# STM32H7B0 register map
File version: 2.3
CPU: CM7 r0p1, little endian, MPU, FPU, 4 interrupt priority bits
Registers are 32-bit, read-write, reset 0x0 unless marked. A register's access mark holds for its fields unless they carry their own. Offsets are from the block's base; [hi:lo] are bit positions; {n}, {i} and the like mark numbered series; 'fields as' and 'values as' point back to an identical list.

## TIM6 — Basic timers
Base 0x40001000
Same registers: TIM7 0x40001400
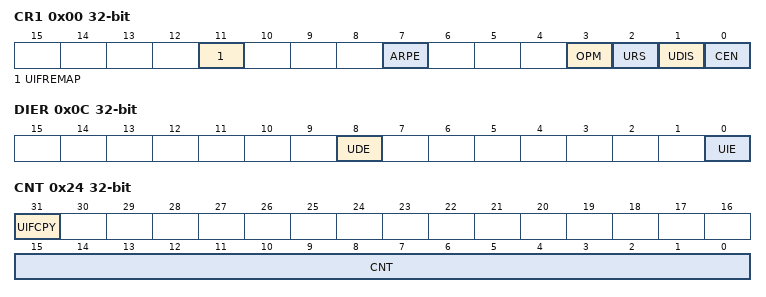
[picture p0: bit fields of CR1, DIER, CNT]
0x00 CR1 — control register 1
  [11] UIFREMAP — UIF status bit remapping
  [7] ARPE — Auto-reload preload enable
  [3] OPM — One-pulse mode
  [2] URS — Update request source
  [1] UDIS — Update disable
  [0] CEN — Counter enable
0x04 CR2 — control register 2
  [6:4] MMS — Master mode selection
0x0C DIER — DMA/Interrupt enable register
  [8] UDE — Update DMA request enable
  [0] UIE — Update interrupt enable
0x10 SR — status register
  [0] UIF — Update interrupt flag
0x14 EGR wo — event generation register
  [0] UG — Update generation
0x24 CNT — counter
  [31] UIFCPY — UIF Copy
  [15:0] CNT — Low counter value
0x28 PSC — prescaler
  [15:0] PSC — Prescaler value
0x2C ARR — auto-reload register
  [15:0] ARR — Low Auto-reload value

## OctoSPII_O_Manager
Base 0x5200B400
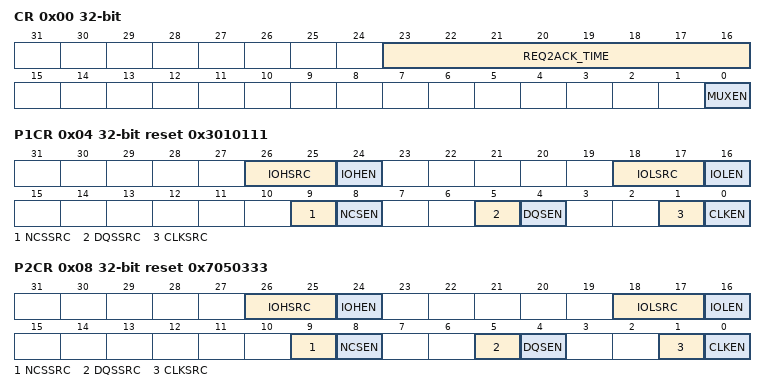
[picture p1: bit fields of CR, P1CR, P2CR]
0x00 CR — OctoSPI IO Manager Control Register
  [23:16] REQ2ACK_TIME — REQ to ACK Time
  [0] MUXEN — Multiplexed mode Enable
0x04 P1CR reset 0x3010111 — OctoSPI IO Manager Port 1 configuration register
  [26:25] IOHSRC
  [24] IOHEN
  [18:17] IOLSRC
  [16] IOLEN
  [9] NCSSRC
  [8] NCSEN
  [5] DQSSRC
  [4] DQSEN
  [1] CLKSRC — CLK/CLKn Source for Port n
  [0] CLKEN — CLK/CLKn Enable for Port n
0x08 P2CR reset 0x7050333 — OctoSPI IO Manager Port 2 configuration register
  [26:25] IOHSRC, [24] IOHEN, [18:17] IOLSRC, [16] IOLEN, [9] NCSSRC, [8] NCSEN, [5] DQSSRC, [4] DQSEN, [1] CLKSRC, [0] CLKEN

## OTFDEC1 — On-The-Fly Decryption engine
Base 0x5200B800
Same registers: OTFDEC2 0x5200BC00
0x00 CR — OTFDEC control register
  [0] ENC — Encryption mode bit
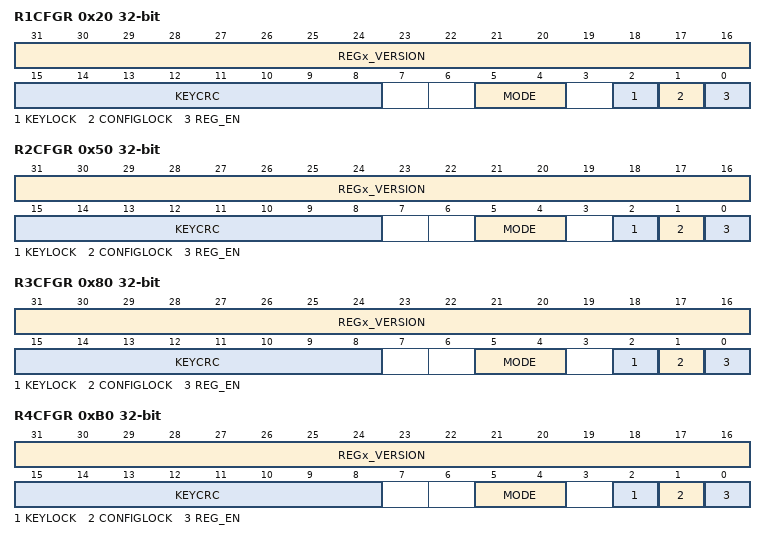
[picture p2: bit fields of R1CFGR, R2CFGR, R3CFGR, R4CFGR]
0x20 R1CFGR access per field — OTFDEC region x configuration register
  [31:16] REGx_VERSION rw — region firmware version
  [15:8] KEYCRC ro — region key 8-bit CRC
  [5:4] MODE rw — operating mode
  [2] KEYLOCK rw — region key lock
  [1] CONFIGLOCK rw — region config lock
  [0] REG_EN rw — region on-the-fly decryption enable
0x24 R1STARTADDR — OTFDEC region x start address register
  [31:0] REGx_START_ADDR — Region AXI start address
0x28 R1ENDADDR reset 0xFFF — OTFDEC region x end address register
  [31:0] REGx_END_ADDR — Region AXI end address
0x2C R1NONCER0 — OTFDEC region x nonce register 0
  [31:0] REGx_NONCE
0x30 R1NONCER1 — OTFDEC region x nonce register 1
  [31:0] REGx_NONCE — Region nonce
{0x4+0x30*i} R{i}KEYR0 wo (i=1..4) — OTFDEC region x key register 0
  [31:0] REGx_KEY
{0x8+0x30*i} R{i}KEYR1 wo (i=1..4) — OTFDEC region x key register 1
  [31:0] REGx_KEY
0x3C R1KEYR2 wo — OTFDEC region x key register 2
  [31:0] REGx_KEY
{0x10+0x30*i} R{i}KEYR3 wo (i=1..4) — OTFDEC region x key register 3
  [31:0] REGx_KEY
0x50 R2CFGR access per field — OTFDEC region x configuration register
  fields as R1CFGR
0x54 R2STARTADDR — OTFDEC region x start address register
  [31:0] REGx_START_ADDR — Region AXI start address
0x58 R2ENDADDR reset 0xFFF — OTFDEC region x end address register
  [31:0] REGx_END_ADDR — Region AXI end address
0x5C R2NONCER0 — OTFDEC region x nonce register 0
  [31:0] REGx_NONCE
0x60 R2NONCER1 — OTFDEC region x nonce register 1
  [31:0] REGx_NONCE — Region nonce, bits [63:32]REGx_NONCE[63:32]
0x6C R2KEYR2 wo — OTFDEC region x key register 2
  [31:0] REGx_KEY_
0x80 R3CFGR access per field — OTFDEC region x configuration register
  fields as R1CFGR
0x84 R3STARTADDR — OTFDEC region x start address register
  [31:0] REGx_START_ADDR — Region AXI start address
0x88 R3ENDADDR reset 0xFFF — OTFDEC region x end address register
  [31:0] REGx_END_ADDR — Region AXI end address
0x8C R4ENDADDR reset 0xFFF — OTFDEC region x end address register
  [31:0] REGx_END_ADDR — Region AXI end address
0x8C R3NONCER0 (alternate view of R4ENDADDR) — OTFDEC region x nonce register 0
  [31:0] REGx_NONCE
0x90 R3NONCER1 — OTFDEC region x nonce register 1
  [31:0] REGx_NONCE
0x9C R3KEYR2 wo — OTFDEC region x key register 2
  [31:0] REGx_KEY
0xB0 R4CFGR access per field — OTFDEC region x configuration register
  fields as R1CFGR
0xB4 R4STARTADDR — OTFDEC region x start address register
  [31:0] REGx_START_ADDR — Region AXI start address
0xBC R4NONCER0 — OTFDEC region x nonce register 0
  [31:0] REGx_NONCE
0xC0 R4NONCER1 — OTFDEC region x nonce register 1
  [31:0] REGx_NONCE
0xCC R4KEYR2 wo — OTFDEC region x key register 2
  [31:0] REGx_KEY
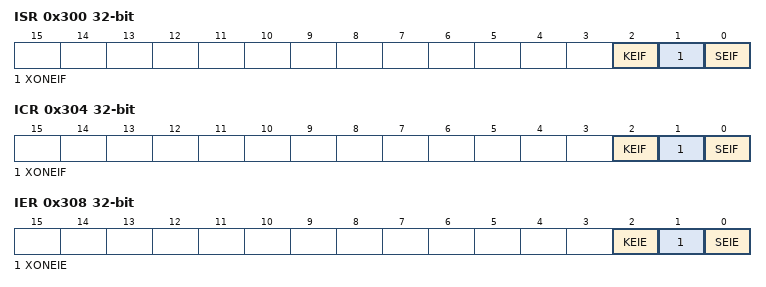
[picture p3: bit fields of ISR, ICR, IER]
0x300 ISR ro — OTFDEC interrupt status register
  [2] KEIF — Key Error Interrupt Flag status
  [1] XONEIF — Execute-only execute-Never Error Interrupt Flag status
  [0] SEIF — Security Error Interrupt Flag status
0x304 ICR ro — OTFDEC interrupt clear register
  [2] KEIF
  [1] XONEIF — Execute-only execute-Never Error Interrupt Flag clear
  [0] SEIF
0x308 IER — OTFDEC interrupt enable register
  [2] KEIE
  [1] XONEIE
  [0] SEIE — Security Error Interrupt Enable
